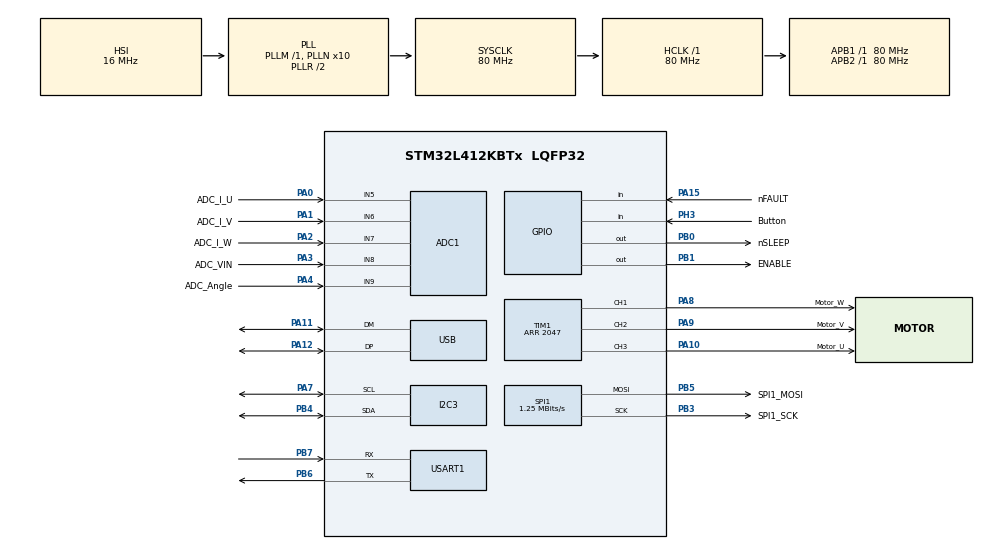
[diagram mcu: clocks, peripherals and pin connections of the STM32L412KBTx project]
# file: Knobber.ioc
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ADC1.Channel-0\#ChannelRegularConversion=ADC_CHANNEL_5
ADC1.Channel-1\#ChannelRegularConversion=ADC_CHANNEL_6
ADC1.Channel-2\#ChannelRegularConversion=ADC_CHANNEL_7
ADC1.Channel-3\#ChannelRegularConversion=ADC_CHANNEL_8
ADC1.Channel-4\#ChannelRegularConversion=ADC_CHANNEL_9
ADC1.ClockPrescaler=ADC_CLOCK_ASYNC_DIV4
ADC1.ContinuousConvMode=ENABLE
ADC1.DMAContinuousRequests=ENABLE
ADC1.EOCSelection=ADC_EOC_SEQ_CONV
ADC1.EnableAnalogWatchDog2=true
ADC1.NbrOfConversion=5
ADC1.NbrOfConversionFlag=1
ADC1.OffsetNumber-0\#ChannelRegularConversion=ADC_OFFSET_NONE
ADC1.OffsetNumber-1\#ChannelRegularConversion=ADC_OFFSET_NONE
ADC1.OffsetNumber-2\#ChannelRegularConversion=ADC_OFFSET_NONE
ADC1.OffsetNumber-3\#ChannelRegularConversion=ADC_OFFSET_NONE
ADC1.OffsetNumber-4\#ChannelRegularConversion=ADC_OFFSET_NONE
ADC1.Rank-0\#ChannelRegularConversion=1
ADC1.Rank-1\#ChannelRegularConversion=2
ADC1.Rank-2\#ChannelRegularConversion=3
ADC1.Rank-3\#ChannelRegularConversion=4
ADC1.Rank-4\#ChannelRegularConversion=5
ADC1.SamplingTime-0\#ChannelRegularConversion=ADC_SAMPLETIME_2CYCLES_5
ADC1.SamplingTime-1\#ChannelRegularConversion=ADC_SAMPLETIME_2CYCLES_5
ADC1.SamplingTime-2\#ChannelRegularConversion=ADC_SAMPLETIME_2CYCLES_5
ADC1.SamplingTime-3\#ChannelRegularConversion=ADC_SAMPLETIME_2CYCLES_5
ADC1.SamplingTime-4\#ChannelRegularConversion=ADC_SAMPLETIME_2CYCLES_5
ADC1.master=1
Dma.ADC1.0.Direction=DMA_PERIPH_TO_MEMORY
Dma.ADC1.0.Instance=DMA1_Channel1
Dma.ADC1.0.MemDataAlignment=DMA_MDATAALIGN_HALFWORD
Dma.ADC1.0.MemInc=DMA_MINC_ENABLE
Dma.ADC1.0.Mode=DMA_NORMAL
Dma.ADC1.0.PeriphDataAlignment=DMA_PDATAALIGN_HALFWORD
Dma.ADC1.0.PeriphInc=DMA_PINC_DISABLE
Dma.ADC1.0.Priority=DMA_PRIORITY_LOW
Dma.I2C3_RX.1.Direction=DMA_PERIPH_TO_MEMORY
Dma.I2C3_RX.1.Instance=DMA1_Channel3
Dma.I2C3_RX.1.MemDataAlignment=DMA_MDATAALIGN_BYTE
Dma.I2C3_RX.1.MemInc=DMA_MINC_ENABLE
Dma.I2C3_RX.1.Mode=DMA_NORMAL
Dma.I2C3_RX.1.PeriphDataAlignment=DMA_PDATAALIGN_BYTE
Dma.I2C3_RX.1.PeriphInc=DMA_PINC_DISABLE
Dma.I2C3_RX.1.Priority=DMA_PRIORITY_LOW
Dma.Request0=ADC1
Dma.Request1=I2C3_RX
I2C3.Timing=0x10D19CE4
Mcu.Family=STM32L4
Mcu.Name=STM32L412KBTx
Mcu.Package=LQFP32
NVIC.ADC1_2_IRQn=true\:2\:0\:true\:false\:true\:true\:true\:true
NVIC.DMA1_Channel1_IRQn=true\:0\:0\:false\:false\:true\:false\:true\:true
NVIC.DMA1_Channel3_IRQn=true\:0\:0\:false\:false\:true\:false\:true\:true
NVIC.I2C3_EV_IRQn=true\:0\:0\:false\:false\:true\:true\:true\:true
NVIC.PriorityGroup=NVIC_PRIORITYGROUP_4
NVIC.USB_IRQn=true\:0\:0\:false\:false\:true\:true\:true\:true
PA0-CK_IN.GPIO_Label=ADC_I_U
PA0-CK_IN.Signal=ADCx_IN5
PA1.GPIO_Label=ADC_I_V
PA1.Signal=ADCx_IN6
PA10.GPIO_Label=Motor_U
PA10.Signal=S_TIM1_CH3
PA11.Mode=Device
PA11.Signal=USB_DM
PA12.Mode=Device
PA12.Signal=USB_DP
PA13\ (JTMS/SWDIO).Mode=Serial_Wire
PA13\ (JTMS/SWDIO).Signal=SYS_JTMS-SWDIO
PA14\ (JTCK/SWCLK).Mode=Serial_Wire
PA14\ (JTCK/SWCLK).Signal=SYS_JTCK-SWCLK
PA15\ (JTDI).GPIO_Label=nFAULT
PA15\ (JTDI).Signal=GPIO_Input
PA2.GPIO_Label=ADC_I_W
PA2.Signal=ADCx_IN7
PA3.GPIO_Label=ADC_VIN
PA3.Signal=ADCx_IN8
PA4.GPIO_Label=ADC_Angle
PA4.Signal=ADCx_IN9
PA7.Mode=I2C
PA7.Signal=I2C3_SCL
PA8.GPIO_Label=Motor_W
PA8.Signal=S_TIM1_CH1
PA9.GPIO_Label=Motor_V
PA9.Signal=S_TIM1_CH2
PB0.GPIO_Label=nSLEEP
PB0.Signal=GPIO_Output
PB1.GPIO_Label=ENABLE
PB1.Signal=GPIO_Output
PB3\ (JTDO/TRACESWO).GPIO_Label=SPI1_SCK
PB3\ (JTDO/TRACESWO).Mode=TX_Only_Simplex_Unidirect_Master
PB3\ (JTDO/TRACESWO).Signal=SPI1_SCK
PB4\ (NJTRST).Mode=I2C
PB4\ (NJTRST).Signal=I2C3_SDA
PB5.GPIO_Label=SPI1_MOSI
PB5.Mode=TX_Only_Simplex_Unidirect_Master
PB5.Signal=SPI1_MOSI
PB6.Mode=Asynchronous
PB6.Signal=USART1_TX
PB7.Mode=Asynchronous
PB7.Signal=USART1_RX
PH3-BOOT0\ (BOOT0).GPIO_Label=Button
PH3-BOOT0\ (BOOT0).Signal=GPIO_Input
ProjectManager.HeapSize=0x200
ProjectManager.StackSize=0x400
ProjectManager.TargetToolchain=STM32CubeIDE
RCC.ADCFreq_Value=80000000
RCC.AHBFreq_Value=80000000
RCC.APB1Freq_Value=80000000
RCC.APB1TimFreq_Value=80000000
RCC.APB2Freq_Value=80000000
RCC.APB2TimFreq_Value=80000000
RCC.CortexFreq_Value=80000000
RCC.HCLKFreq_Value=80000000
RCC.HSE_VALUE=8000000
RCC.HSI48_VALUE=48000000
RCC.HSI_VALUE=16000000
RCC.LSE_VALUE=32768
RCC.MSIClockRange=RCC_MSIRANGE_11
RCC.MSI_VALUE=48000000
RCC.PLLN=10
RCC.PLLSourceVirtual=RCC_PLLSOURCE_HSI
RCC.SYSCLKFreq_VALUE=80000000
RCC.SYSCLKSource=RCC_SYSCLKSOURCE_PLLCLK
RCC.USBFreq_Value=48000000
RCC.VCOOutputFreq_Value=160000000
SH.ADCx_IN5.0=ADC1_IN5,IN5-Single-Ended
SH.ADCx_IN6.0=ADC1_IN6,IN6-Single-Ended
SH.ADCx_IN7.0=ADC1_IN7,IN7-Single-Ended
SH.ADCx_IN8.0=ADC1_IN8,IN8-Single-Ended
SH.ADCx_IN9.0=ADC1_IN9,IN9-Single-Ended
SH.S_TIM1_CH1.0=TIM1_CH1,PWM Generation1 CH1
SH.S_TIM1_CH2.0=TIM1_CH2,PWM Generation2 CH2
SH.S_TIM1_CH3.0=TIM1_CH3,PWM Generation3 CH3
SPI1.BaudRatePrescaler=SPI_BAUDRATEPRESCALER_64
SPI1.CalculateBaudRate=1.25 MBits/s
SPI1.DataSize=SPI_DATASIZE_8BIT
SPI1.Direction=SPI_DIRECTION_2LINES
SPI1.Mode=SPI_MODE_MASTER
SPI1.VirtualType=VM_MASTER
TIM1.AutoReloadPreload=TIM_AUTORELOAD_PRELOAD_ENABLE
TIM1.Channel-PWM\ Generation1\ CH1=TIM_CHANNEL_1
TIM1.Channel-PWM\ Generation2\ CH2=TIM_CHANNEL_2
TIM1.Channel-PWM\ Generation3\ CH3=TIM_CHANNEL_3
TIM1.Period=2047
TIM1.Pulse-PWM\ Generation1\ CH1=1024
TIM1.Pulse-PWM\ Generation2\ CH2=1024
TIM1.Pulse-PWM\ Generation3\ CH3=1024
USART1.VirtualMode-Asynchronous=VM_ASYNC
USB_DEVICE.CLASS_NAME_FS=HID
USB_DEVICE.LANGID_STRING=1031
USB_DEVICE.MANUFACTURER_STRING=Hehe hani selber gmacht
USB_DEVICE.PRODUCT_STRING_HID_FS=Knobber
USB_DEVICE.VirtualMode=Hid
USB_DEVICE.VirtualModeFS=Hid_FS
VP_TIM1_VS_ClockSourceINT.Mode=Internal
VP_USB_DEVICE_VS_USB_DEVICE_HID_FS.Mode=HID_FS
board=custom

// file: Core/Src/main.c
/* USER CODE BEGIN Header */
/**
  ******************************************************************************
  * @file           : main.c
  * @brief          : Main program body
  ******************************************************************************
  * @attention
  *
  * Copyright (c) 2025 STMicroelectronics.
  * All rights reserved.
  *
  * This software is licensed under terms that can be found in the LICENSE file
  * in the root directory of this software component.
  * If no LICENSE file comes with this software, it is provided AS-IS.
  *
  ******************************************************************************
  */
/* USER CODE END Header */
#include "main.h"
#include "usb_device.h"

/* USER CODE BEGIN Includes */

#include "application.h"

/* USER CODE END Includes */

ADC_HandleTypeDef hadc1;
DMA_HandleTypeDef hdma_adc1;

I2C_HandleTypeDef hi2c3;
DMA_HandleTypeDef hdma_i2c3_rx;

SPI_HandleTypeDef hspi1;

TIM_HandleTypeDef htim1;

UART_HandleTypeDef huart1;

void SystemClock_Config(void);
static void MX_GPIO_Init(void);
static void MX_DMA_Init(void);
static void MX_ADC1_Init(void);
static void MX_I2C3_Init(void);
static void MX_TIM1_Init(void);
static void MX_USART1_UART_Init(void);
static void MX_SPI1_Init(void);

/* USER CODE BEGIN 0 */

extern USBD_HandleTypeDef hUsbDeviceFS;

/* USER CODE END 0 */

int main(void)
{

  /* MCU Configuration--------------------------------------------------------*/

  /* Reset of all peripherals, Initializes the Flash interface and the Systick. */
  HAL_Init();

  /* Configure the system clock */
  SystemClock_Config();

  /* Initialize all configured peripherals */
  MX_GPIO_Init();
  MX_DMA_Init();
  MX_ADC1_Init();
  MX_I2C3_Init();
  MX_TIM1_Init();
  MX_USART1_UART_Init();
  MX_SPI1_Init();
  MX_USB_DEVICE_Init();

  /* Infinite loop */
  /* USER CODE BEGIN WHILE */

  init();
  while (1)
  {
	  mainloop();

    /* USER CODE END WHILE */

  }
}

void SystemClock_Config(void)
{
  RCC_OscInitTypeDef RCC_OscInitStruct = {0};
  RCC_ClkInitTypeDef RCC_ClkInitStruct = {0};

  /** Configure the main internal regulator output voltage
  */
  if (HAL_PWREx_ControlVoltageScaling(PWR_REGULATOR_VOLTAGE_SCALE1) != HAL_OK)
  {
    Error_Handler();
  }

  /** Initializes the RCC Oscillators according to the specified parameters
  * in the RCC_OscInitTypeDef structure.
  */
  RCC_OscInitStruct.OscillatorType = RCC_OSCILLATORTYPE_HSI|RCC_OSCILLATORTYPE_MSI;
  RCC_OscInitStruct.HSIState = RCC_HSI_ON;
  RCC_OscInitStruct.HSICalibrationValue = RCC_HSICALIBRATION_DEFAULT;
  RCC_OscInitStruct.MSIState = RCC_MSI_ON;
  RCC_OscInitStruct.MSICalibrationValue = 0;
  RCC_OscInitStruct.MSIClockRange = RCC_MSIRANGE_11;
  RCC_OscInitStruct.PLL.PLLState = RCC_PLL_ON;
  RCC_OscInitStruct.PLL.PLLSource = RCC_PLLSOURCE_HSI;
  RCC_OscInitStruct.PLL.PLLM = 1;
  RCC_OscInitStruct.PLL.PLLN = 10;
  RCC_OscInitStruct.PLL.PLLQ = RCC_PLLQ_DIV2;
  RCC_OscInitStruct.PLL.PLLR = RCC_PLLR_DIV2;
  if (HAL_RCC_OscConfig(&RCC_OscInitStruct) != HAL_OK)
  {
    Error_Handler();
  }

  /** Initializes the CPU, AHB and APB buses clocks
  */
  RCC_ClkInitStruct.ClockType = RCC_CLOCKTYPE_HCLK|RCC_CLOCKTYPE_SYSCLK
                              |RCC_CLOCKTYPE_PCLK1|RCC_CLOCKTYPE_PCLK2;
  RCC_ClkInitStruct.SYSCLKSource = RCC_SYSCLKSOURCE_PLLCLK;
  RCC_ClkInitStruct.AHBCLKDivider = RCC_SYSCLK_DIV1;
  RCC_ClkInitStruct.APB1CLKDivider = RCC_HCLK_DIV1;
  RCC_ClkInitStruct.APB2CLKDivider = RCC_HCLK_DIV1;

  if (HAL_RCC_ClockConfig(&RCC_ClkInitStruct, FLASH_LATENCY_4) != HAL_OK)
  {
    Error_Handler();
  }
}

static void MX_ADC1_Init(void)
{

  ADC_MultiModeTypeDef multimode = {0};
  ADC_ChannelConfTypeDef sConfig = {0};

  /** Common config
  */
  hadc1.Instance = ADC1;
  hadc1.Init.ClockPrescaler = ADC_CLOCK_ASYNC_DIV4;
  hadc1.Init.Resolution = ADC_RESOLUTION_12B;
  hadc1.Init.DataAlign = ADC_DATAALIGN_RIGHT;
  hadc1.Init.ScanConvMode = ADC_SCAN_ENABLE;
  hadc1.Init.EOCSelection = ADC_EOC_SEQ_CONV;
  hadc1.Init.LowPowerAutoWait = DISABLE;
  hadc1.Init.ContinuousConvMode = ENABLE;
  hadc1.Init.NbrOfConversion = 5;
  hadc1.Init.DiscontinuousConvMode = DISABLE;
  hadc1.Init.ExternalTrigConv = ADC_SOFTWARE_START;
  hadc1.Init.ExternalTrigConvEdge = ADC_EXTERNALTRIGCONVEDGE_NONE;
  hadc1.Init.DMAContinuousRequests = ENABLE;
  hadc1.Init.Overrun = ADC_OVR_DATA_PRESERVED;
  hadc1.Init.OversamplingMode = DISABLE;
  if (HAL_ADC_Init(&hadc1) != HAL_OK)
  {
    Error_Handler();
  }

  /** Configure the ADC multi-mode
  */
  multimode.Mode = ADC_MODE_INDEPENDENT;
  if (HAL_ADCEx_MultiModeConfigChannel(&hadc1, &multimode) != HAL_OK)
  {
    Error_Handler();
  }

  /** Configure Regular Channel
  */
  sConfig.Channel = ADC_CHANNEL_5;
  sConfig.Rank = ADC_REGULAR_RANK_1;
  sConfig.SamplingTime = ADC_SAMPLETIME_2CYCLES_5;
  sConfig.SingleDiff = ADC_SINGLE_ENDED;
  sConfig.OffsetNumber = ADC_OFFSET_NONE;
  sConfig.Offset = 0;
  if (HAL_ADC_ConfigChannel(&hadc1, &sConfig) != HAL_OK)
  {
    Error_Handler();
  }

  /** Configure Regular Channel
  */
  sConfig.Channel = ADC_CHANNEL_6;
  sConfig.Rank = ADC_REGULAR_RANK_2;
  if (HAL_ADC_ConfigChannel(&hadc1, &sConfig) != HAL_OK)
  {
    Error_Handler();
  }

  /** Configure Regular Channel
  */
  sConfig.Channel = ADC_CHANNEL_7;
  sConfig.Rank = ADC_REGULAR_RANK_3;
  if (HAL_ADC_ConfigChannel(&hadc1, &sConfig) != HAL_OK)
  {
    Error_Handler();
  }

  /** Configure Regular Channel
  */
  sConfig.Channel = ADC_CHANNEL_8;
  sConfig.Rank = ADC_REGULAR_RANK_4;
  if (HAL_ADC_ConfigChannel(&hadc1, &sConfig) != HAL_OK)
  {
    Error_Handler();
  }

  /** Configure Regular Channel
  */
  sConfig.Channel = ADC_CHANNEL_9;
  sConfig.Rank = ADC_REGULAR_RANK_5;
  if (HAL_ADC_ConfigChannel(&hadc1, &sConfig) != HAL_OK)
  {
    Error_Handler();
  }

}

static void MX_I2C3_Init(void)
{

  hi2c3.Instance = I2C3;
  hi2c3.Init.Timing = 0x10D19CE4;
  hi2c3.Init.OwnAddress1 = 0;
  hi2c3.Init.AddressingMode = I2C_ADDRESSINGMODE_7BIT;
  hi2c3.Init.DualAddressMode = I2C_DUALADDRESS_DISABLE;
  hi2c3.Init.OwnAddress2 = 0;
  hi2c3.Init.OwnAddress2Masks = I2C_OA2_NOMASK;
  hi2c3.Init.GeneralCallMode = I2C_GENERALCALL_DISABLE;
  hi2c3.Init.NoStretchMode = I2C_NOSTRETCH_DISABLE;
  if (HAL_I2C_Init(&hi2c3) != HAL_OK)
  {
    Error_Handler();
  }

  /** Configure Analogue filter
  */
  if (HAL_I2CEx_ConfigAnalogFilter(&hi2c3, I2C_ANALOGFILTER_ENABLE) != HAL_OK)
  {
    Error_Handler();
  }

  /** Configure Digital filter
  */
  if (HAL_I2CEx_ConfigDigitalFilter(&hi2c3, 0) != HAL_OK)
  {
    Error_Handler();
  }

}

static void MX_SPI1_Init(void)
{

  /* SPI1 parameter configuration*/
  hspi1.Instance = SPI1;
  hspi1.Init.Mode = SPI_MODE_MASTER;
  hspi1.Init.Direction = SPI_DIRECTION_2LINES;
  hspi1.Init.DataSize = SPI_DATASIZE_8BIT;
  hspi1.Init.CLKPolarity = SPI_POLARITY_LOW;
  hspi1.Init.CLKPhase = SPI_PHASE_1EDGE;
  hspi1.Init.NSS = SPI_NSS_SOFT;
  hspi1.Init.BaudRatePrescaler = SPI_BAUDRATEPRESCALER_64;
  hspi1.Init.FirstBit = SPI_FIRSTBIT_MSB;
  hspi1.Init.TIMode = SPI_TIMODE_DISABLE;
  hspi1.Init.CRCCalculation = SPI_CRCCALCULATION_DISABLE;
  hspi1.Init.CRCPolynomial = 7;
  hspi1.Init.CRCLength = SPI_CRC_LENGTH_DATASIZE;
  hspi1.Init.NSSPMode = SPI_NSS_PULSE_ENABLE;
  if (HAL_SPI_Init(&hspi1) != HAL_OK)
  {
    Error_Handler();
  }

}

static void MX_TIM1_Init(void)
{

  TIM_ClockConfigTypeDef sClockSourceConfig = {0};
  TIM_MasterConfigTypeDef sMasterConfig = {0};
  TIM_OC_InitTypeDef sConfigOC = {0};
  TIM_BreakDeadTimeConfigTypeDef sBreakDeadTimeConfig = {0};

  htim1.Instance = TIM1;
  htim1.Init.Prescaler = 0;
  htim1.Init.CounterMode = TIM_COUNTERMODE_UP;
  htim1.Init.Period = 2047;
  htim1.Init.ClockDivision = TIM_CLOCKDIVISION_DIV1;
  htim1.Init.RepetitionCounter = 0;
  htim1.Init.AutoReloadPreload = TIM_AUTORELOAD_PRELOAD_ENABLE;
  if (HAL_TIM_Base_Init(&htim1) != HAL_OK)
  {
    Error_Handler();
  }
  sClockSourceConfig.ClockSource = TIM_CLOCKSOURCE_INTERNAL;
  if (HAL_TIM_ConfigClockSource(&htim1, &sClockSourceConfig) != HAL_OK)
  {
    Error_Handler();
  }
  if (HAL_TIM_PWM_Init(&htim1) != HAL_OK)
  {
    Error_Handler();
  }
  sMasterConfig.MasterOutputTrigger = TIM_TRGO_RESET;
  sMasterConfig.MasterOutputTrigger2 = TIM_TRGO2_RESET;
  sMasterConfig.MasterSlaveMode = TIM_MASTERSLAVEMODE_DISABLE;
  if (HAL_TIMEx_MasterConfigSynchronization(&htim1, &sMasterConfig) != HAL_OK)
  {
    Error_Handler();
  }
  sConfigOC.OCMode = TIM_OCMODE_PWM1;
  sConfigOC.Pulse = 1024;
  sConfigOC.OCPolarity = TIM_OCPOLARITY_HIGH;
  sConfigOC.OCNPolarity = TIM_OCNPOLARITY_HIGH;
  sConfigOC.OCFastMode = TIM_OCFAST_DISABLE;
  sConfigOC.OCIdleState = TIM_OCIDLESTATE_RESET;
  sConfigOC.OCNIdleState = TIM_OCNIDLESTATE_RESET;
  if (HAL_TIM_PWM_ConfigChannel(&htim1, &sConfigOC, TIM_CHANNEL_1) != HAL_OK)
  {
    Error_Handler();
  }
  if (HAL_TIM_PWM_ConfigChannel(&htim1, &sConfigOC, TIM_CHANNEL_2) != HAL_OK)
  {
    Error_Handler();
  }
  if (HAL_TIM_PWM_ConfigChannel(&htim1, &sConfigOC, TIM_CHANNEL_3) != HAL_OK)
  {
    Error_Handler();
  }
  sBreakDeadTimeConfig.OffStateRunMode = TIM_OSSR_DISABLE;
  sBreakDeadTimeConfig.OffStateIDLEMode = TIM_OSSI_DISABLE;
  sBreakDeadTimeConfig.LockLevel = TIM_LOCKLEVEL_OFF;
  sBreakDeadTimeConfig.DeadTime = 0;
  sBreakDeadTimeConfig.BreakState = TIM_BREAK_DISABLE;
  sBreakDeadTimeConfig.BreakPolarity = TIM_BREAKPOLARITY_HIGH;
  sBreakDeadTimeConfig.BreakFilter = 0;
  sBreakDeadTimeConfig.Break2State = TIM_BREAK2_DISABLE;
  sBreakDeadTimeConfig.Break2Polarity = TIM_BREAK2POLARITY_HIGH;
  sBreakDeadTimeConfig.Break2Filter = 0;
  sBreakDeadTimeConfig.AutomaticOutput = TIM_AUTOMATICOUTPUT_DISABLE;
  if (HAL_TIMEx_ConfigBreakDeadTime(&htim1, &sBreakDeadTimeConfig) != HAL_OK)
  {
    Error_Handler();
  }
  HAL_TIM_MspPostInit(&htim1);

}

static void MX_USART1_UART_Init(void)
{

  huart1.Instance = USART1;
  huart1.Init.BaudRate = 115200;
  huart1.Init.WordLength = UART_WORDLENGTH_8B;
  huart1.Init.StopBits = UART_STOPBITS_1;
  huart1.Init.Parity = UART_PARITY_NONE;
  huart1.Init.Mode = UART_MODE_TX_RX;
  huart1.Init.HwFlowCtl = UART_HWCONTROL_NONE;
  huart1.Init.OverSampling = UART_OVERSAMPLING_16;
  huart1.Init.OneBitSampling = UART_ONE_BIT_SAMPLE_DISABLE;
  huart1.AdvancedInit.AdvFeatureInit = UART_ADVFEATURE_NO_INIT;
  if (HAL_UART_Init(&huart1) != HAL_OK)
  {
    Error_Handler();
  }

}

static void MX_DMA_Init(void)
{

  /* DMA controller clock enable */
  __HAL_RCC_DMA1_CLK_ENABLE();

  /* DMA interrupt init */
  /* DMA1_Channel1_IRQn interrupt configuration */
  HAL_NVIC_SetPriority(DMA1_Channel1_IRQn, 0, 0);
  HAL_NVIC_EnableIRQ(DMA1_Channel1_IRQn);
  /* DMA1_Channel3_IRQn interrupt configuration */
  HAL_NVIC_SetPriority(DMA1_Channel3_IRQn, 0, 0);
  HAL_NVIC_EnableIRQ(DMA1_Channel3_IRQn);

}

static void MX_GPIO_Init(void)
{
  GPIO_InitTypeDef GPIO_InitStruct = {0};

  /* GPIO Ports Clock Enable */
  __HAL_RCC_GPIOA_CLK_ENABLE();
  __HAL_RCC_GPIOB_CLK_ENABLE();
  __HAL_RCC_GPIOH_CLK_ENABLE();

  /*Configure GPIO pin Output Level */
  HAL_GPIO_WritePin(GPIOB, nSLEEP_Pin|ENABLE_Pin, GPIO_PIN_RESET);

  /*Configure GPIO pins : nSLEEP_Pin ENABLE_Pin */
  GPIO_InitStruct.Pin = nSLEEP_Pin|ENABLE_Pin;
  GPIO_InitStruct.Mode = GPIO_MODE_OUTPUT_PP;
  GPIO_InitStruct.Pull = GPIO_NOPULL;
  GPIO_InitStruct.Speed = GPIO_SPEED_FREQ_LOW;
  HAL_GPIO_Init(GPIOB, &GPIO_InitStruct);

  /*Configure GPIO pin : nFAULT_Pin */
  GPIO_InitStruct.Pin = nFAULT_Pin;
  GPIO_InitStruct.Mode = GPIO_MODE_INPUT;
  GPIO_InitStruct.Pull = GPIO_NOPULL;
  HAL_GPIO_Init(nFAULT_GPIO_Port, &GPIO_InitStruct);

  /*Configure GPIO pin : Button_Pin */
  GPIO_InitStruct.Pin = Button_Pin;
  GPIO_InitStruct.Mode = GPIO_MODE_INPUT;
  GPIO_InitStruct.Pull = GPIO_NOPULL;
  HAL_GPIO_Init(Button_GPIO_Port, &GPIO_InitStruct);

}

void Error_Handler(void)
{
  __disable_irq();
  while (1)
  {
  }
}
